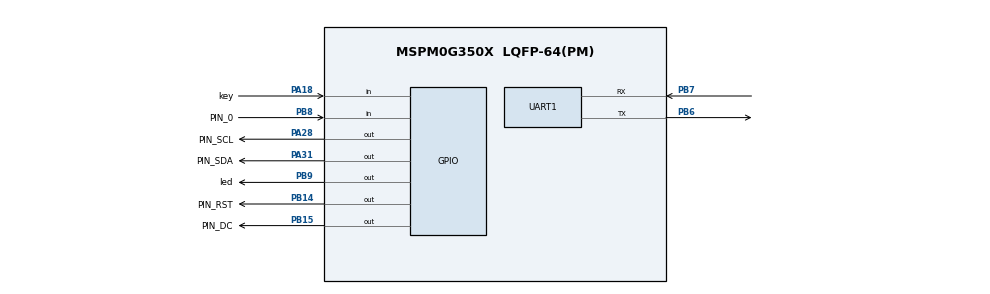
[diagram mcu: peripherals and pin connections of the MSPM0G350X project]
/**
 *
 * @cliArgs --device "MSPM0G350X" --part "Default" --package "LQFP-64(PM)" --product "mspm0_sdk@2.10.00.04"
 * @versions {"tool":"1.28.1+4785"}
 */

/**
 * Import the modules used in this configuration.
 */
const GPIO    = scripting.addModule("/ti/driverlib/GPIO", {}, false);
const GPIO1   = GPIO.addInstance();
const GPIO2   = GPIO.addInstance();
const GPIO3   = GPIO.addInstance();
const GPIO4   = GPIO.addInstance();
const GPIO5   = GPIO.addInstance();
const GPIO6   = GPIO.addInstance();
const GPIO7   = GPIO.addInstance();
const SYSCTL  = scripting.addModule("/ti/driverlib/SYSCTL");
const SYSTICK = scripting.addModule("/ti/driverlib/SYSTICK");
const TIMER   = scripting.addModule("/ti/driverlib/TIMER", {}, false);
const TIMER1  = TIMER.addInstance();
const UART    = scripting.addModule("/ti/driverlib/UART", {}, false);
const UART1   = UART.addInstance();

/**
 * Write custom configuration values to the imported modules.
 */
const divider7       = system.clockTree["PLL_PDIV"];
divider7.divideValue = 2;

const divider9       = system.clockTree["UDIV"];
divider9.divideValue = 2;

const gate7  = system.clockTree["MFCLKGATE"];
gate7.enable = true;

const multiplier2         = system.clockTree["PLL_QDIV"];
multiplier2.multiplyValue = 5;

const mux8       = system.clockTree["HSCLKMUX"];
mux8.inputSelect = "HSCLKMUX_SYSPLL2X";

GPIO1.$name                         = "OLED_RST";
GPIO1.associatedPins[0].$name       = "PIN_RST";
GPIO1.associatedPins[0].pin.$assign = "PB14";

const Board = scripting.addModule("/ti/driverlib/Board", {}, false);

GPIO2.$name                         = "OLED_DC";
GPIO2.associatedPins[0].$name       = "PIN_DC";
GPIO2.associatedPins[0].pin.$assign = "PB15";

GPIO3.$name                         = "OLED_SCL";
GPIO3.associatedPins[0].$name       = "PIN_SCL";
GPIO3.associatedPins[0].pin.$assign = "PA28";

GPIO4.$name                         = "OLED_SDA";
GPIO4.associatedPins[0].$name       = "PIN_SDA";
GPIO4.associatedPins[0].pin.$assign = "PA31";

GPIO5.$name                              = "KEY";
GPIO5.associatedPins[0].$name            = "key";
GPIO5.associatedPins[0].direction        = "INPUT";
GPIO5.associatedPins[0].internalResistor = "PULL_UP";
GPIO5.associatedPins[0].pin.$assign      = "PA18";

GPIO6.$name                         = "LED";
GPIO6.associatedPins[0].$name       = "led";
GPIO6.associatedPins[0].pin.$assign = "PB9";

GPIO7.$name                         = "USER_KEY";
GPIO7.associatedPins[0].$name       = "PIN_0";
GPIO7.associatedPins[0].direction   = "INPUT";
GPIO7.associatedPins[0].pin.$assign = "PB8";

SYSCTL.forceDefaultClkConfig = true;
SYSCTL.clockTreeEn           = true;

SYSTICK.periodEnable  = true;
SYSTICK.systickEnable = true;
SYSTICK.period        = 16777216;

TIMER1.$name              = "TIMER_0";
TIMER1.timerClkPrescale   = 32;
TIMER1.timerMode          = "PERIODIC";
TIMER1.timerPeriod        = "5 ms";
TIMER1.timerStartTimer    = true;
TIMER1.interrupts         = ["ZERO"];
TIMER1.interruptPriority  = "1";
TIMER1.peripheral.$assign = "TIMG0";

UART1.$name                            = "UART_1";
UART1.targetBaudRate                   = 115200;
UART1.interruptPriority                = "3";
UART1.peripheral.$assign               = "UART1";
UART1.peripheral.rxPin.$assign         = "PB7";
UART1.peripheral.txPin.$assign         = "PB6";
UART1.txPinConfig.direction            = scripting.forceWrite("OUTPUT");
UART1.txPinConfig.hideOutputInversion  = scripting.forceWrite(false);
UART1.txPinConfig.onlyInternalResistor = scripting.forceWrite(false);
UART1.txPinConfig.passedPeripheralType = scripting.forceWrite("Digital");
UART1.txPinConfig.$name                = "ti_driverlib_gpio_GPIOPinGeneric6";
UART1.rxPinConfig.hideOutputInversion  = scripting.forceWrite(false);
UART1.rxPinConfig.onlyInternalResistor = scripting.forceWrite(false);
UART1.rxPinConfig.passedPeripheralType = scripting.forceWrite("Digital");
UART1.rxPinConfig.$name                = "ti_driverlib_gpio_GPIOPinGeneric7";

/**
 * Pinmux solution for unlocked pins/peripherals. This ensures that minor changes to the automatic solver in a future
 * version of the tool will not impact the pinmux you originally saw.  These lines can be completely deleted in order to
 * re-solve from scratch.
 */
Board.peripheral.$suggestSolution          = "DEBUGSS";
Board.peripheral.swclkPin.$suggestSolution = "PA20";
Board.peripheral.swdioPin.$suggestSolution = "PA19";
